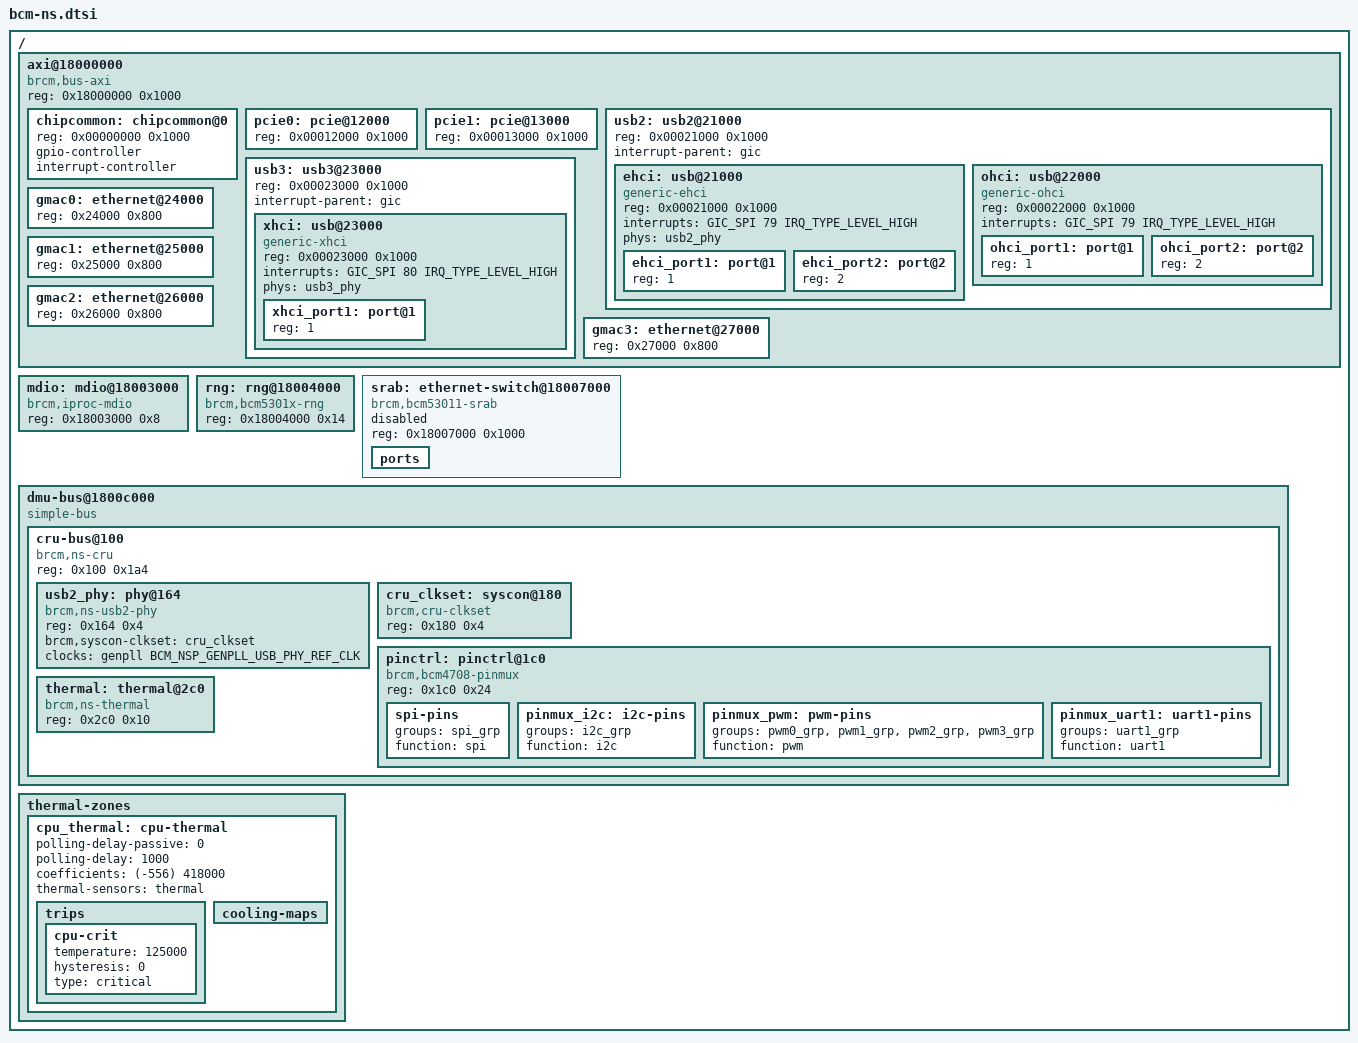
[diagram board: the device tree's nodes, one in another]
// SPDX-License-Identifier: GPL-2.0-or-later OR MIT

#include <dt-bindings/clock/bcm-nsp.h>
#include <dt-bindings/gpio/gpio.h>
#include <dt-bindings/input/input.h>
#include <dt-bindings/interrupt-controller/irq.h>
#include <dt-bindings/interrupt-controller/arm-gic.h>

/ {
	axi@18000000 {
		compatible = "brcm,bus-axi";
		reg = <0x18000000 0x1000>;
		ranges = <0x00000000 0x18000000 0x00100000>;
		#address-cells = <1>;
		#size-cells = <1>;

		chipcommon: chipcommon@0 {
			reg = <0x00000000 0x1000>;

			gpio-controller;
			#gpio-cells = <2>;
			interrupt-controller;
			#interrupt-cells = <2>;
		};

		pcie0: pcie@12000 {
			reg = <0x00012000 0x1000>;
		};

		pcie1: pcie@13000 {
			reg = <0x00013000 0x1000>;
		};

		usb2: usb2@21000 {
			reg = <0x00021000 0x1000>;

			#address-cells = <1>;
			#size-cells = <1>;
			ranges;

			interrupt-parent = <&gic>;

			ehci: usb@21000 {
				#usb-cells = <0>;

				compatible = "generic-ehci";
				reg = <0x00021000 0x1000>;
				interrupts = <GIC_SPI 79 IRQ_TYPE_LEVEL_HIGH>;
				phys = <&usb2_phy>;

				#address-cells = <1>;
				#size-cells = <0>;

				ehci_port1: port@1 {
					reg = <1>;
					#trigger-source-cells = <0>;
				};

				ehci_port2: port@2 {
					reg = <2>;
					#trigger-source-cells = <0>;
				};
			};

			ohci: usb@22000 {
				#usb-cells = <0>;

				compatible = "generic-ohci";
				reg = <0x00022000 0x1000>;
				interrupts = <GIC_SPI 79 IRQ_TYPE_LEVEL_HIGH>;

				#address-cells = <1>;
				#size-cells = <0>;

				ohci_port1: port@1 {
					reg = <1>;
					#trigger-source-cells = <0>;
				};

				ohci_port2: port@2 {
					reg = <2>;
					#trigger-source-cells = <0>;
				};
			};
		};

		usb3: usb3@23000 {
			reg = <0x00023000 0x1000>;

			#address-cells = <1>;
			#size-cells = <1>;
			ranges;

			interrupt-parent = <&gic>;

			xhci: usb@23000 {
				#usb-cells = <0>;

				compatible = "generic-xhci";
				reg = <0x00023000 0x1000>;
				interrupts = <GIC_SPI 80 IRQ_TYPE_LEVEL_HIGH>;
				phys = <&usb3_phy>;
				phy-names = "usb";

				#address-cells = <1>;
				#size-cells = <0>;

				xhci_port1: port@1 {
					reg = <1>;
					#trigger-source-cells = <0>;
				};
			};
		};

		gmac0: ethernet@24000 {
			reg = <0x24000 0x800>;
		};

		gmac1: ethernet@25000 {
			reg = <0x25000 0x800>;
		};

		gmac2: ethernet@26000 {
			reg = <0x26000 0x800>;
		};

		gmac3: ethernet@27000 {
			reg = <0x27000 0x800>;
		};
	};

	mdio: mdio@18003000 {
		compatible = "brcm,iproc-mdio";
		reg = <0x18003000 0x8>;
		#size-cells = <0>;
		#address-cells = <1>;
	};

	rng: rng@18004000 {
		compatible = "brcm,bcm5301x-rng";
		reg = <0x18004000 0x14>;
	};

	srab: ethernet-switch@18007000 {
		compatible = "brcm,bcm53011-srab", "brcm,bcm5301x-srab";
		reg = <0x18007000 0x1000>;

		status = "disabled";

		/* ports are defined in board DTS */
		ports {
			#address-cells = <1>;
			#size-cells = <0>;
		};
	};

	dmu-bus@1800c000 {
		compatible = "simple-bus";
		ranges = <0 0x1800c000 0x1000>;
		#address-cells = <1>;
		#size-cells = <1>;

		cru-bus@100 {
			compatible = "brcm,ns-cru", "simple-mfd";
			reg = <0x100 0x1a4>;
			ranges;
			#address-cells = <1>;
			#size-cells = <1>;

			usb2_phy: phy@164 {
				compatible = "brcm,ns-usb2-phy";
				reg = <0x164 0x4>;
				brcm,syscon-clkset = <&cru_clkset>;
				clocks = <&genpll BCM_NSP_GENPLL_USB_PHY_REF_CLK>;
				clock-names = "phy-ref-clk";
				#phy-cells = <0>;
			};

			cru_clkset: syscon@180 {
				compatible = "brcm,cru-clkset", "syscon";
				reg = <0x180 0x4>;
			};

			pinctrl: pinctrl@1c0 {
				compatible = "brcm,bcm4708-pinmux";
				reg = <0x1c0 0x24>;
				reg-names = "cru_gpio_control";

				spi-pins {
					groups = "spi_grp";
					function = "spi";
				};

				pinmux_i2c: i2c-pins {
					groups = "i2c_grp";
					function = "i2c";
				};

				pinmux_pwm: pwm-pins {
					groups = "pwm0_grp", "pwm1_grp",
						 "pwm2_grp", "pwm3_grp";
					function = "pwm";
				};

				pinmux_uart1: uart1-pins {
					groups = "uart1_grp";
					function = "uart1";
				};
			};

			thermal: thermal@2c0 {
				compatible = "brcm,ns-thermal";
				reg = <0x2c0 0x10>;
				#thermal-sensor-cells = <0>;
			};
		};
	};

	thermal-zones {
		cpu_thermal: cpu-thermal {
			polling-delay-passive = <0>;
			polling-delay = <1000>;
			coefficients = <(-556) 418000>;
			thermal-sensors = <&thermal>;

			trips {
				cpu-crit {
					temperature = <125000>;
					hysteresis = <0>;
					type = "critical";
				};
			};

			cooling-maps {
			};
		};
	};
};
